# STM32F746 register map
File version: 1.5
CPU: CM7 r0p1, little endian, MPU, FPU, 4 interrupt priority bits
Registers are 32-bit, read-write, reset 0x0 unless marked. A register's access mark holds for its fields unless they carry their own. Offsets are from the block's base; [hi:lo] are bit positions; {n}, {i} and the like mark numbered series.

## Ethernet_PTP — Ethernet: Precision time protocol
Base 0x40028700
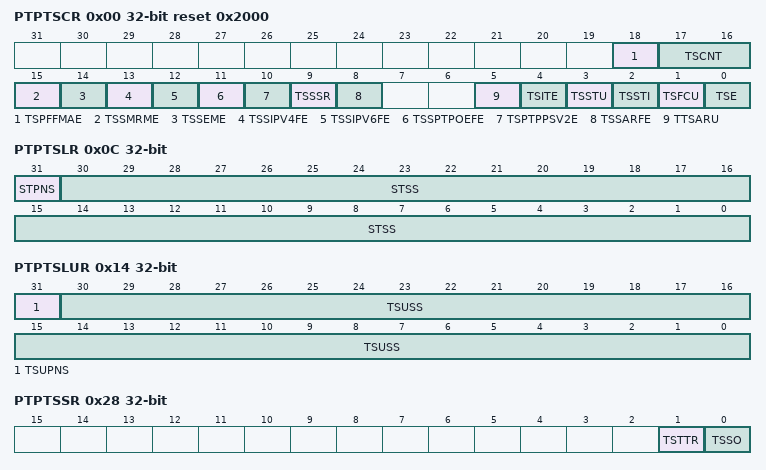
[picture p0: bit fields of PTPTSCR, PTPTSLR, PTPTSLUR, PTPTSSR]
0x00 PTPTSCR reset 0x2000 — Ethernet PTP time stamp control register
  [18] TSPFFMAE, [17:16] TSCNT, [15] TSSMRME, [14] TSSEME, [13] TSSIPV4FE, [12] TSSIPV6FE, [11] TSSPTPOEFE, [10] TSPTPPSV2E, [9] TSSSR, [8] TSSARFE, [5] TTSARU, [4] TSITE, [3] TSSTU, [2] TSSTI, [1] TSFCU, [0] TSE
0x04 PTPSSIR — Ethernet PTP subsecond increment register
  [7:0] STSSI
0x08 PTPTSHR ro — Ethernet PTP time stamp high register
  [31:0] STS
0x0C PTPTSLR ro — Ethernet PTP time stamp low register
  [31] STPNS, [30:0] STSS
0x10 PTPTSHUR — Ethernet PTP time stamp high update register
  [31:0] TSUS
0x14 PTPTSLUR — Ethernet PTP time stamp low update register
  [31] TSUPNS, [30:0] TSUSS
0x18 PTPTSAR — Ethernet PTP time stamp addend register
  [31:0] TSA
0x1C PTPTTHR — Ethernet PTP target time high register
  [31:0] TTSH — 0
0x20 PTPTTLR — Ethernet PTP target time low register
  [31:0] TTSL
0x28 PTPTSSR ro — Ethernet PTP time stamp status register
  [1] TSTTR, [0] TSSO
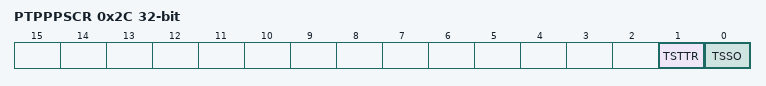
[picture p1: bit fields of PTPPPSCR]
0x2C PTPPPSCR ro — Ethernet PTP PPS control register
  [1] TSTTR, [0] TSSO

## CRC — Cryptographic processor
Base 0x40023000
0x00 DR reset 0xFFFFFFFF — Data register
  [31:0] DR — Data Register
0x00 DR8 8-bit reset 0xFF (alternate view of DR) — Data register - byte sized
  [7:0] DR8 — Data register bits
0x00 DR16 16-bit reset 0xFFFF (alternate view of DR) — Data register - half-word sized
  [15:0] DR16 — Data register bits
0x04 IDR — Independent Data register
  [7:0] IDR
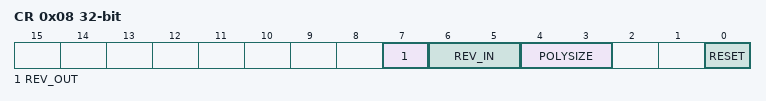
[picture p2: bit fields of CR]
0x08 CR wo — Control register
  [7] REV_OUT rw — Reverse output data
    0=Normal (Bit order not affected); 1=Reversed (Bit reversed output)
  [6:5] REV_IN rw — Reverse input data
    0=Normal (Bit order not affected); 1=Byte (Bit reversal done by byte); 2=HalfWord (Bit reversal done by half-word); 3=Word (Bit reversal done by word)
  [4:3] POLYSIZE rw — Polynomial size
    0=32-bit polynomial; 1=16-bit polynomial; 2=8-bit polynomial; 3=7-bit polynomial
  [0] RESET — RESET bit
    1=Resets the CRC calculation unit and sets the data register to 0xFFFF FFFF
0x10 INIT — Initial CRC value
  [31:0] INIT — Programmable initial CRC value
0x14 POL — CRC polynomial
  [31:0] POL — Programmable polynomial

## EXTI — External interrupt/event controller
Base 0x40013C00
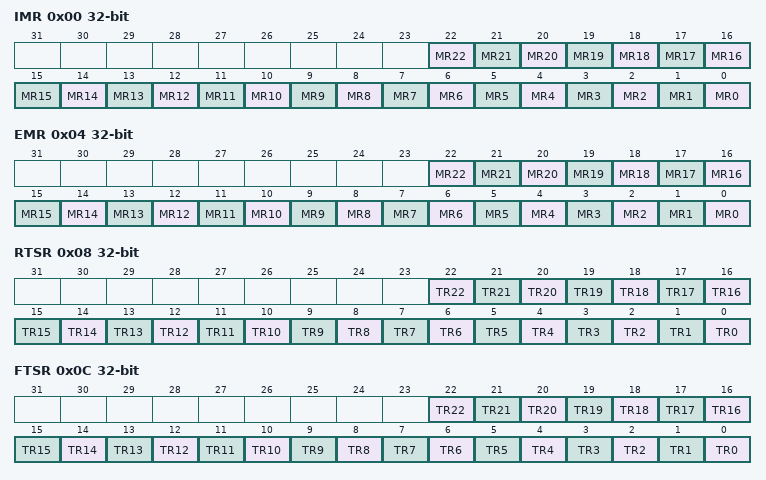
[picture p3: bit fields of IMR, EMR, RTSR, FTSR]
0x00 IMR — Interrupt mask register (EXTI_IMR)
  [n] MR{n} (n=0..22) — Interrupt Mask on line {n}
    0=Masked (Interrupt request line is masked); 1=Unmasked (Interrupt request line is unmasked)
0x04 EMR — Event mask register (EXTI_EMR)
  [n] MR{n} (n=0..22) — Event Mask on line {n}
    0=Masked (Event request line is masked); 1=Unmasked (Event request line is unmasked)
0x08 RTSR — Rising Trigger selection register (EXTI_RTSR)
  [n] TR{n} (n=0..22) — Rising trigger event configuration of line {n}
    0=Disabled (Rising edge trigger is disabled); 1=Enabled (Rising edge trigger is enabled)
0x0C FTSR — Falling Trigger selection register (EXTI_FTSR)
  [n] TR{n} (n=0..22) — Falling trigger event configuration of line {n}
    0=Disabled (Falling edge trigger is disabled); 1=Enabled (Falling edge trigger is enabled)
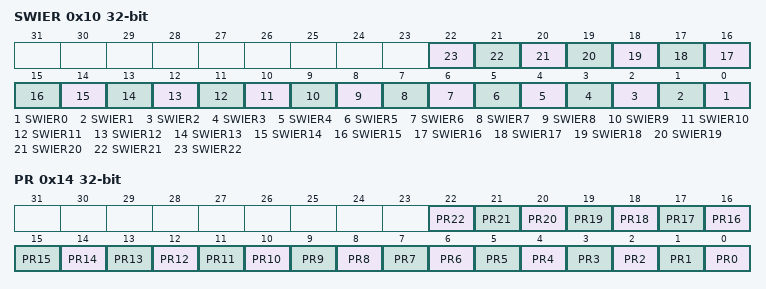
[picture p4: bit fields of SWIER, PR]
0x10 SWIER — Software interrupt event register (EXTI_SWIER)
  [n] SWIER{n} (n=0..22) — Software Interrupt on line {n}
    on write: 1=Pend (Generates an interrupt request)
0x14 PR — Pending register (EXTI_PR)
  [n] PR{n} (n=0..22) write-1-clears — Pending bit {n}
    on read: 0=NotPending (No trigger request occurred); 1=Pending (Selected trigger request occurred) | on write: 1=Clears pending bit

## CEC — HDMI-CEC controller
Base 0x40006C00
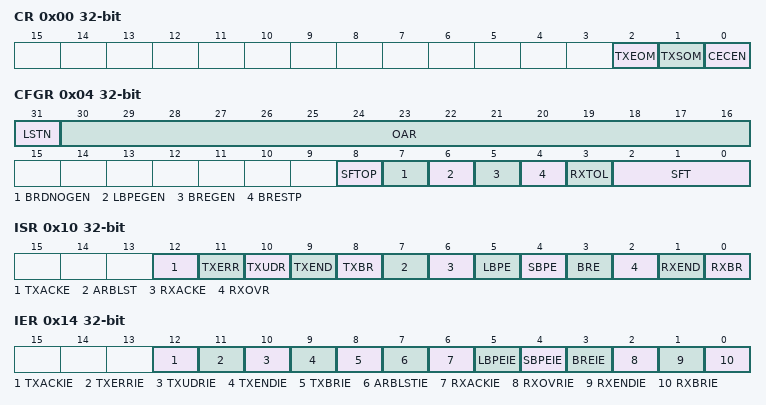
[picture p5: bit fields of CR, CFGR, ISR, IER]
0x00 CR — control register
  [2] TXEOM — Tx End Of Message
  [1] TXSOM — Tx start of message
  [0] CECEN — CEC Enable
0x04 CFGR — configuration register
  [31] LSTN — Listen mode
  [30:16] OAR — Own addresses configuration
  [8] SFTOP — SFT Option Bit
  [7] BRDNOGEN — Avoid Error-Bit Generation in Broadcast
  [6] LBPEGEN — Generate Error-Bit on Long Bit Period Error
  [5] BREGEN — Generate error-bit on bit rising error
  [4] BRESTP — Rx-stop on bit rising error
  [3] RXTOL — Rx-Tolerance
  [2:0] SFT — Signal Free Time
0x08 TXDR wo — Tx data register
  [7:0] TXD — Tx Data register
0x0C RXDR ro — Rx Data Register
  [7:0] RXDR — CEC Rx Data Register
0x10 ISR — Interrupt and Status Register
  [12] TXACKE — Tx-Missing acknowledge error
  [11] TXERR — Tx-Error
  [10] TXUDR — Tx-Buffer Underrun
  [9] TXEND — End of Transmission
  [8] TXBR — Tx-Byte Request
  [7] ARBLST — Arbitration Lost
  [6] RXACKE — Rx-Missing Acknowledge
  [5] LBPE — Rx-Long Bit Period Error
  [4] SBPE — Rx-Short Bit period error
  [3] BRE — Rx-Bit rising error
  [2] RXOVR — Rx-Overrun
  [1] RXEND — End Of Reception
  [0] RXBR — Rx-Byte Received
0x14 IER — interrupt enable register
  [12] TXACKIE — Tx-Missing Acknowledge Error Interrupt Enable
  [11] TXERRIE — Tx-Error Interrupt Enable
  [10] TXUDRIE — Tx-Underrun interrupt enable
  [9] TXENDIE — Tx-End of message interrupt enable
  [8] TXBRIE — Tx-Byte Request Interrupt Enable
  [7] ARBLSTIE — Arbitration Lost Interrupt Enable
  [6] RXACKIE — Rx-Missing Acknowledge Error Interrupt Enable
  [5] LBPEIE — Long Bit Period Error Interrupt Enable
  [4] SBPEIE — Short Bit Period Error Interrupt Enable
  [3] BREIE — Bit Rising Error Interrupt Enable
  [2] RXOVRIE — Rx-Buffer Overrun Interrupt Enable
  [1] RXENDIE — End Of Reception Interrupt Enable
  [0] RXBRIE — Rx-Byte Received Interrupt Enable
